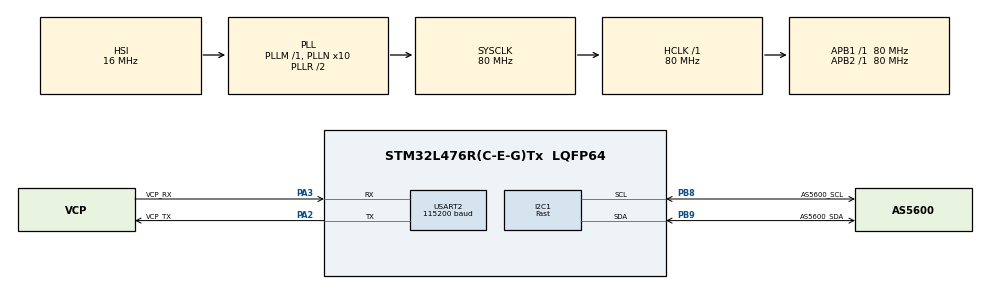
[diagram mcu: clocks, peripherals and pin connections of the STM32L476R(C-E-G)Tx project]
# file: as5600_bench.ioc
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I2C1.I2C_Speed_Mode=I2C_Fast
I2C1.Timing=0x00702991
Mcu.Family=STM32L4
Mcu.Name=STM32L476R(C-E-G)Tx
Mcu.Package=LQFP64
NVIC.PriorityGroup=NVIC_PRIORITYGROUP_4
NVIC.USART2_IRQn=true\:5\:0\:false\:false\:true\:true\:true\:true
PA13\ (JTMS-SWDIO).Mode=Serial_Wire
PA13\ (JTMS-SWDIO).Signal=SYS_JTMS-SWDIO
PA14\ (JTCK-SWCLK).Mode=Serial_Wire
PA14\ (JTCK-SWCLK).Signal=SYS_JTCK-SWCLK
PA2.GPIO_Label=VCP_TX
PA2.Mode=Asynchronous
PA2.Signal=USART2_TX
PA3.GPIO_Label=VCP_RX
PA3.Mode=Asynchronous
PA3.Signal=USART2_RX
PB8.GPIO_Label=AS5600_SCL
PB8.GPIO_PuPd=GPIO_NOPULL
PB8.Mode=I2C
PB8.Signal=I2C1_SCL
PB9.GPIO_Label=AS5600_SDA
PB9.GPIO_PuPd=GPIO_NOPULL
PB9.Mode=I2C
PB9.Signal=I2C1_SDA
ProjectManager.HeapSize=0x200
ProjectManager.StackSize=0x400
ProjectManager.TargetToolchain=STM32CubeIDE
RCC.ADCFreq_Value=64000000
RCC.AHBFreq_Value=80000000
RCC.APB1Freq_Value=80000000
RCC.APB1TimFreq_Value=80000000
RCC.APB2Freq_Value=80000000
RCC.APB2TimFreq_Value=80000000
RCC.CortexFreq_Value=80000000
RCC.HCLKFreq_Value=80000000
RCC.HSE_VALUE=8000000
RCC.HSI_VALUE=16000000
RCC.LSE_VALUE=32768
RCC.MSI_VALUE=4000000
RCC.PLLN=10
RCC.PLLSourceVirtual=RCC_PLLSOURCE_HSI
RCC.SYSCLKFreq_VALUE=80000000
RCC.SYSCLKSource=RCC_SYSCLKSOURCE_PLLCLK
RCC.USBFreq_Value=64000000
RCC.VCOOutputFreq_Value=160000000
TIM2.Period=4294967295
TIM2.Prescaler=79
USART2.BaudRate=115200
USART2.VirtualMode-Asynchronous=VM_ASYNC
VP_TIM2_VS_ClockSourceINT.Mode=Internal
board=custom

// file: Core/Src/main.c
/* USER CODE BEGIN Header */
/**
  ******************************************************************************
  * @file           : main.c
  * @brief          : Main program body
  ******************************************************************************
  * @attention
  *
  * Copyright (c) 2026 STMicroelectronics.
  * All rights reserved.
  *
  * This software is licensed under terms that can be found in the LICENSE file
  * in the root directory of this software component.
  * If no LICENSE file comes with this software, it is provided AS-IS.
  *
  ******************************************************************************
  */
/* USER CODE END Header */
#include "main.h"

/* USER CODE BEGIN Includes */
#include "enc_cli.h"   /* AS5600 bench-test app (as5600.c driver, enc_cli.c, serial_io.c) */
/* USER CODE END Includes */

I2C_HandleTypeDef hi2c1;

TIM_HandleTypeDef htim2;

UART_HandleTypeDef huart2;

void SystemClock_Config(void);
static void MX_GPIO_Init(void);
static void MX_I2C1_Init(void);
static void MX_USART2_UART_Init(void);
static void MX_TIM2_Init(void);

int main(void)
{

  /* MCU Configuration--------------------------------------------------------*/

  /* Reset of all peripherals, Initializes the Flash interface and the Systick. */
  HAL_Init();

  /* Configure the system clock */
  SystemClock_Config();

  /* Initialize all configured peripherals */
  MX_GPIO_Init();
  MX_I2C1_Init();
  MX_USART2_UART_Init();
  MX_TIM2_Init();
  /* USER CODE BEGIN 2 */
  /* Console, 1 MHz timestamp timer, sensor probe + magnet check, start stream. */
  enc_app_init(&hi2c1, &huart2, &htim2);
  /* USER CODE END 2 */

  /* Infinite loop */
  while (1)
  {

    /* USER CODE BEGIN 3 */
    enc_app_poll();   /* non-blocking: CLI, 200 Hz tracker, stream, reconnect */
  }
  /* USER CODE END 3 */
}

void SystemClock_Config(void)
{
  RCC_OscInitTypeDef RCC_OscInitStruct = {0};
  RCC_ClkInitTypeDef RCC_ClkInitStruct = {0};

  /** Configure the main internal regulator output voltage
  */
  if (HAL_PWREx_ControlVoltageScaling(PWR_REGULATOR_VOLTAGE_SCALE1) != HAL_OK)
  {
    Error_Handler();
  }

  /** Initializes the RCC Oscillators according to the specified parameters
  * in the RCC_OscInitTypeDef structure.
  */
  RCC_OscInitStruct.OscillatorType = RCC_OSCILLATORTYPE_HSI;
  RCC_OscInitStruct.HSIState = RCC_HSI_ON;
  RCC_OscInitStruct.HSICalibrationValue = RCC_HSICALIBRATION_DEFAULT;
  RCC_OscInitStruct.PLL.PLLState = RCC_PLL_ON;
  RCC_OscInitStruct.PLL.PLLSource = RCC_PLLSOURCE_HSI;
  RCC_OscInitStruct.PLL.PLLM = 1;
  RCC_OscInitStruct.PLL.PLLN = 10;
  RCC_OscInitStruct.PLL.PLLP = RCC_PLLP_DIV7;
  RCC_OscInitStruct.PLL.PLLQ = RCC_PLLQ_DIV2;
  RCC_OscInitStruct.PLL.PLLR = RCC_PLLR_DIV2;
  if (HAL_RCC_OscConfig(&RCC_OscInitStruct) != HAL_OK)
  {
    Error_Handler();
  }

  /** Initializes the CPU, AHB and APB buses clocks
  */
  RCC_ClkInitStruct.ClockType = RCC_CLOCKTYPE_HCLK|RCC_CLOCKTYPE_SYSCLK
                              |RCC_CLOCKTYPE_PCLK1|RCC_CLOCKTYPE_PCLK2;
  RCC_ClkInitStruct.SYSCLKSource = RCC_SYSCLKSOURCE_PLLCLK;
  RCC_ClkInitStruct.AHBCLKDivider = RCC_SYSCLK_DIV1;
  RCC_ClkInitStruct.APB1CLKDivider = RCC_HCLK_DIV1;
  RCC_ClkInitStruct.APB2CLKDivider = RCC_HCLK_DIV1;

  if (HAL_RCC_ClockConfig(&RCC_ClkInitStruct, FLASH_LATENCY_4) != HAL_OK)
  {
    Error_Handler();
  }
}

static void MX_I2C1_Init(void)
{

  hi2c1.Instance = I2C1;
  hi2c1.Init.Timing = 0x00702991;
  hi2c1.Init.OwnAddress1 = 0;
  hi2c1.Init.AddressingMode = I2C_ADDRESSINGMODE_7BIT;
  hi2c1.Init.DualAddressMode = I2C_DUALADDRESS_DISABLE;
  hi2c1.Init.OwnAddress2 = 0;
  hi2c1.Init.OwnAddress2Masks = I2C_OA2_NOMASK;
  hi2c1.Init.GeneralCallMode = I2C_GENERALCALL_DISABLE;
  hi2c1.Init.NoStretchMode = I2C_NOSTRETCH_DISABLE;
  if (HAL_I2C_Init(&hi2c1) != HAL_OK)
  {
    Error_Handler();
  }

  /** Configure Analogue filter
  */
  if (HAL_I2CEx_ConfigAnalogFilter(&hi2c1, I2C_ANALOGFILTER_ENABLE) != HAL_OK)
  {
    Error_Handler();
  }

  /** Configure Digital filter
  */
  if (HAL_I2CEx_ConfigDigitalFilter(&hi2c1, 0) != HAL_OK)
  {
    Error_Handler();
  }

}

static void MX_TIM2_Init(void)
{

  TIM_ClockConfigTypeDef sClockSourceConfig = {0};
  TIM_MasterConfigTypeDef sMasterConfig = {0};

  htim2.Instance = TIM2;
  htim2.Init.Prescaler = 79;
  htim2.Init.CounterMode = TIM_COUNTERMODE_UP;
  htim2.Init.Period = 4294967295;
  htim2.Init.ClockDivision = TIM_CLOCKDIVISION_DIV1;
  htim2.Init.AutoReloadPreload = TIM_AUTORELOAD_PRELOAD_DISABLE;
  if (HAL_TIM_Base_Init(&htim2) != HAL_OK)
  {
    Error_Handler();
  }
  sClockSourceConfig.ClockSource = TIM_CLOCKSOURCE_INTERNAL;
  if (HAL_TIM_ConfigClockSource(&htim2, &sClockSourceConfig) != HAL_OK)
  {
    Error_Handler();
  }
  sMasterConfig.MasterOutputTrigger = TIM_TRGO_RESET;
  sMasterConfig.MasterSlaveMode = TIM_MASTERSLAVEMODE_DISABLE;
  if (HAL_TIMEx_MasterConfigSynchronization(&htim2, &sMasterConfig) != HAL_OK)
  {
    Error_Handler();
  }

}

static void MX_USART2_UART_Init(void)
{

  huart2.Instance = USART2;
  huart2.Init.BaudRate = 115200;
  huart2.Init.WordLength = UART_WORDLENGTH_8B;
  huart2.Init.StopBits = UART_STOPBITS_1;
  huart2.Init.Parity = UART_PARITY_NONE;
  huart2.Init.Mode = UART_MODE_TX_RX;
  huart2.Init.HwFlowCtl = UART_HWCONTROL_NONE;
  huart2.Init.OverSampling = UART_OVERSAMPLING_16;
  huart2.Init.OneBitSampling = UART_ONE_BIT_SAMPLE_DISABLE;
  huart2.AdvancedInit.AdvFeatureInit = UART_ADVFEATURE_NO_INIT;
  if (HAL_UART_Init(&huart2) != HAL_OK)
  {
    Error_Handler();
  }

}

static void MX_GPIO_Init(void)
{

  /* GPIO Ports Clock Enable */
  __HAL_RCC_GPIOA_CLK_ENABLE();
  __HAL_RCC_GPIOB_CLK_ENABLE();

}

void Error_Handler(void)
{
  __disable_irq();
  while (1)
  {
  }
}
